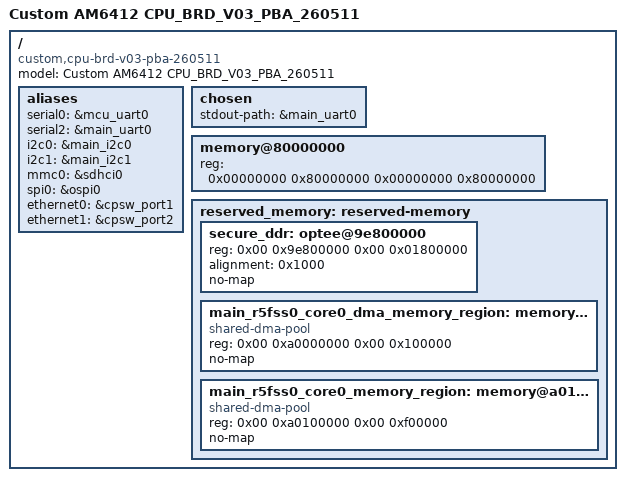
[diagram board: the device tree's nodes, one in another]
/dts-v1/;

#include <dt-bindings/gpio/gpio.h>
#include <dt-bindings/net/ti-dp83867.h>
#include "k3-am642.dtsi"
#include "k3-am6412-custom-pinmux.facts.dtsi"
#include "k3-am6412-custom-final-overrides.dtsi"

/ {
	model = "Custom AM6412 CPU_BRD_V03_PBA_260511";
	compatible = "custom,cpu-brd-v03-pba-260511", "custom,am6412-board", "ti,am642";
	/* Root-managed build DTS set derived from workflow final. */

	aliases {
		serial0 = &mcu_uart0;
		serial2 = &main_uart0;
		i2c0 = &main_i2c0;
		i2c1 = &main_i2c1;
		mmc0 = &sdhci0;
		spi0 = &ospi0;
		ethernet0 = &cpsw_port1;
		ethernet1 = &cpsw_port2;
	};

	chosen {
		stdout-path = &main_uart0;
	};

	memory@80000000 {
		device_type = "memory";
		reg = <0x00000000 0x80000000 0x00000000 0x80000000>;
	};

	reserved_memory: reserved-memory {
		#address-cells = <2>;
		#size-cells = <2>;
		ranges;

		secure_ddr: optee@9e800000 {
			reg = <0x00 0x9e800000 0x00 0x01800000>;
			alignment = <0x1000>;
			no-map;
		};

		main_r5fss0_core0_dma_memory_region: memory@a0000000 {
			compatible = "shared-dma-pool";
			reg = <0x00 0xa0000000 0x00 0x100000>;
			no-map;
		};

		main_r5fss0_core0_memory_region: memory@a0100000 {
			compatible = "shared-dma-pool";
			reg = <0x00 0xa0100000 0x00 0xf00000>;
			no-map;
		};
	};

	/* TODO: review whether reserved-memory baseline should be kept as-is for this board's final product policy. */
	/* TODO: add regulator and PMIC tree after power policy is reviewed. */
	/* TODO: SERDES0 PCIe/USB3/FPGA/VITA routing policy is still unresolved. */
	/* TODO: TPM compatible for U15 and PI6ULS5V9509UEX attachment for U21 remain unresolved. */
};

#include "k3-am64-ti-ipc-firmware.dtsi"
